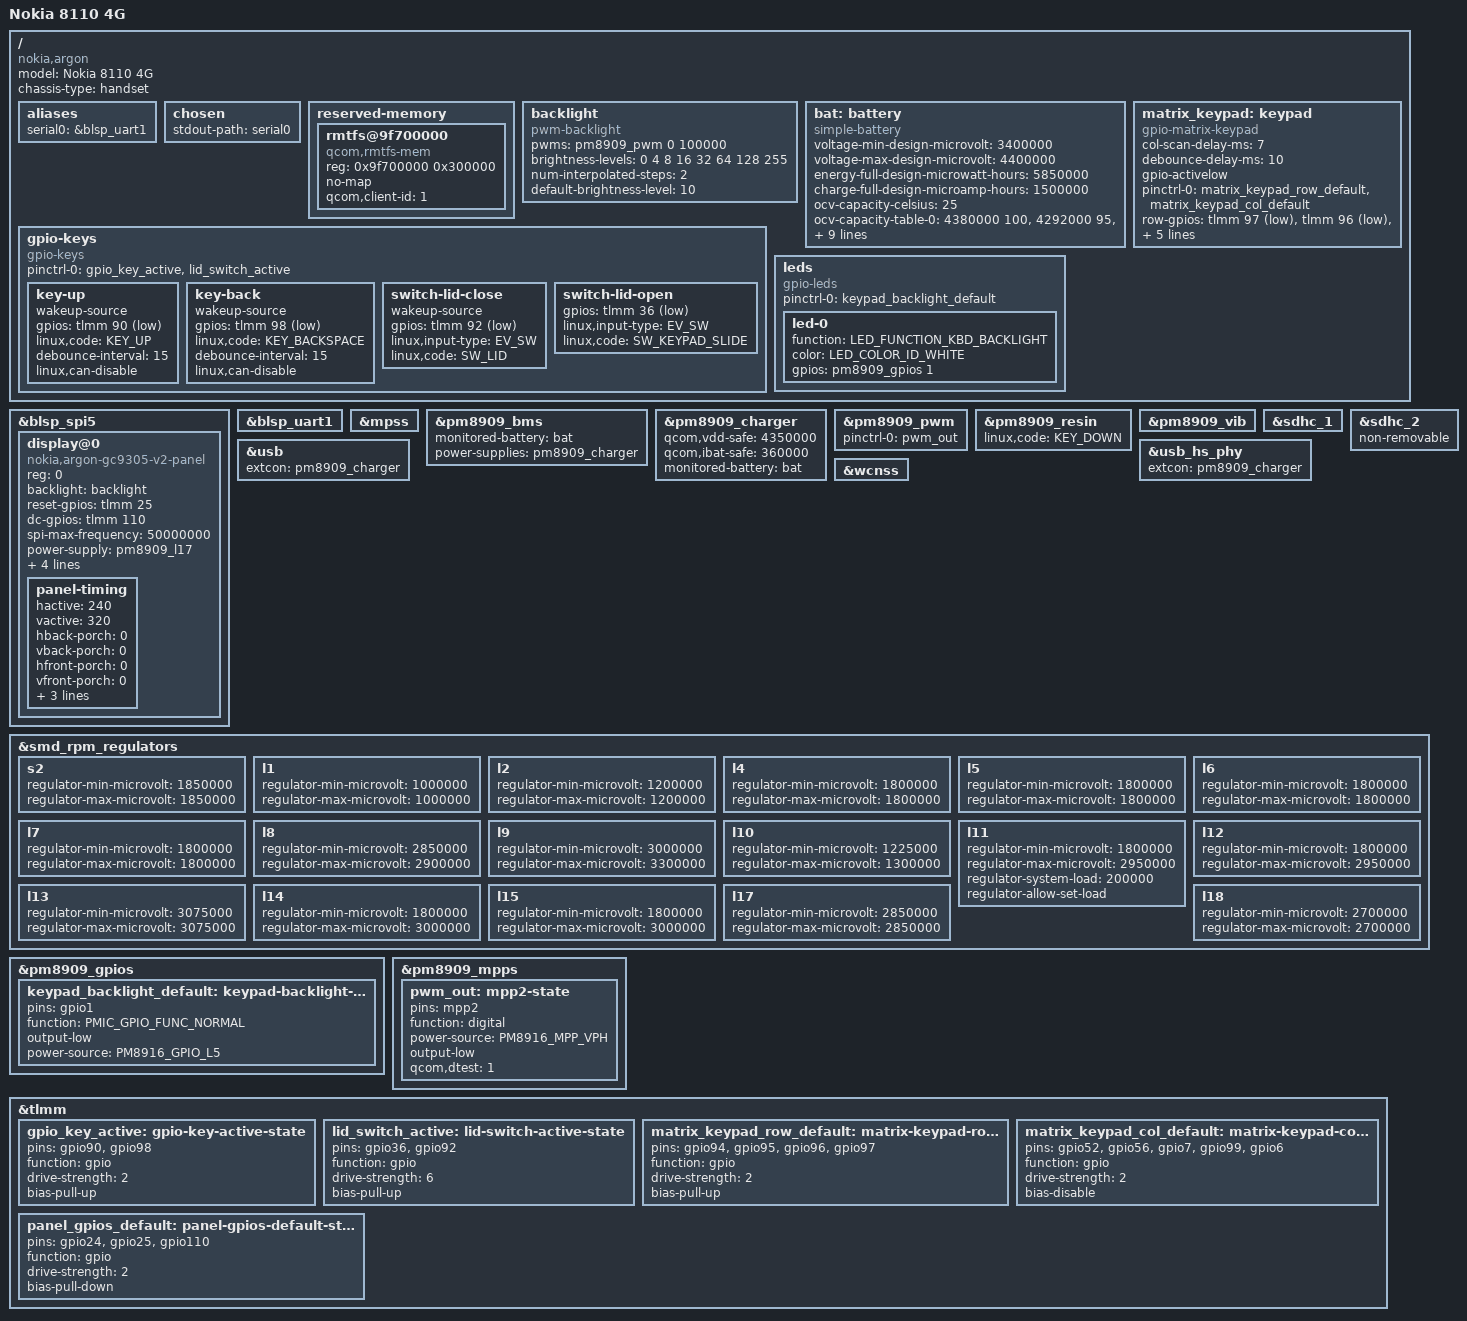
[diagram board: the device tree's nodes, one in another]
// SPDX-License-Identifier: GPL-2.0-only
/dts-v1/;
#include "qcom-msm8909-pm8909.dtsi"
#include <dt-bindings/gpio/gpio.h>
#include <dt-bindings/input/input.h>
#include <dt-bindings/leds/common.h>
#include <dt-bindings/pinctrl/qcom,pmic-gpio.h>
#include <dt-bindings/pinctrl/qcom,pmic-mpp.h>

/ {
	model = "Nokia 8110 4G";
	compatible = "nokia,argon", "qcom,msm8905", "qcom,msm8909";
	chassis-type = "handset";

	aliases {
		serial0 = &blsp_uart1;
	};

	chosen {
		stdout-path = "serial0";
	};

	reserved-memory {
		/delete-node/ rmtfs@87c00000;
		/* On downstream, this address is set by the bootloader */
		rmtfs@9f700000 {
			compatible = "qcom,rmtfs-mem";
			reg = <0x9f700000 0x300000>;
			no-map;

			qcom,client-id = <1>;
		};
	};

	backlight: backlight {
		compatible = "pwm-backlight";
		pwms = <&pm8909_pwm 0 100000>;

		brightness-levels = <0 4 8 16 32 64 128 255>;
		num-interpolated-steps = <2>;
		default-brightness-level = <10>;
	};

	bat: battery {
		compatible = "simple-battery";
		voltage-min-design-microvolt = <3400000>;
		voltage-max-design-microvolt = <4400000>;
		energy-full-design-microwatt-hours = <5850000>;
		charge-full-design-microamp-hours = <1500000>;

		ocv-capacity-celsius = <25>;
		ocv-capacity-table-0 = <4380000 100>, <4292000 95>,
			<4234000 90>, <4190000 85>, <4158000 80>, <4125000 75>,
			<4090000 70>, <4040000 65>, <3988000 60>, <3950000 55>,
			<3925000 50>, <3880000 45>, <3840000 40>, <3800000 35>,
			<3784000 30>, <3761000 25>, <3743000 20>, <3722000 16>,
			<3702000 13>, <3690000 11>, <3688000 10>, <3687000 9>,
			<3685000 8>, <3683000 7>, <3677000 6>, <3656000 5>,
			<3612000 4>, <3554000 3>, <3462000 2>, <3322000 1>,
			<3000000 0>;
	};

	gpio-keys {
		compatible = "gpio-keys";
		pinctrl-0 = <&gpio_key_active &lid_switch_active>;
		pinctrl-names = "default";

		key-up {
			wakeup-source;
			gpios = <&tlmm 90 GPIO_ACTIVE_LOW>;
			linux,code = <KEY_UP>;
			debounce-interval = <15>;
			linux,can-disable;
		};

		key-back {
			wakeup-source;
			gpios = <&tlmm 98 GPIO_ACTIVE_LOW>;
			linux,code = <KEY_BACKSPACE>;
			debounce-interval = <15>;
			linux,can-disable;
		};

		switch-lid-close {
			wakeup-source;
			gpios = <&tlmm 92 GPIO_ACTIVE_LOW>;
			linux,input-type = <EV_SW>;
			linux,code = <SW_LID>;
		};

		switch-lid-open {
			gpios = <&tlmm 36 GPIO_ACTIVE_LOW>;
			linux,input-type = <EV_SW>;
			linux,code = <SW_KEYPAD_SLIDE>;
		};
	};

	matrix_keypad: keypad {
		compatible = "gpio-matrix-keypad";

		col-scan-delay-ms = <7>;
		debounce-delay-ms = <10>;
		gpio-activelow;
		pinctrl-0 = <&matrix_keypad_row_default &matrix_keypad_col_default>;
		pinctrl-names = "default";

		row-gpios = <&tlmm 97 GPIO_ACTIVE_LOW
			&tlmm 96 GPIO_ACTIVE_LOW
			&tlmm 95 GPIO_ACTIVE_LOW
			&tlmm 94 GPIO_ACTIVE_LOW>;

		col-gpios = <&tlmm 52 GPIO_ACTIVE_LOW
			&tlmm 56 GPIO_ACTIVE_LOW
			&tlmm 7 GPIO_ACTIVE_LOW
			&tlmm 99 GPIO_ACTIVE_LOW
			&tlmm 6 GPIO_ACTIVE_LOW>;

		linux,keymap = <
			MATRIX_KEY(0, 0, KEY_PICKUP_PHONE)
			MATRIX_KEY(0, 1, KEY_1)
			MATRIX_KEY(0, 2, KEY_4)
			MATRIX_KEY(0, 3, KEY_7)
			MATRIX_KEY(0, 4, KEY_NUMERIC_STAR)

			MATRIX_KEY(1, 0, KEY_LEFT)
			MATRIX_KEY(1, 1, KEY_2)
			MATRIX_KEY(1, 2, KEY_5)
			MATRIX_KEY(1, 3, KEY_8)
			MATRIX_KEY(1, 4, KEY_0)

			MATRIX_KEY(2, 0, BTN_LEFT)
			MATRIX_KEY(2, 1, KEY_3)
			MATRIX_KEY(2, 2, KEY_6)
			MATRIX_KEY(2, 3, KEY_9)
			MATRIX_KEY(2, 4, KEY_NUMERIC_POUND)

			MATRIX_KEY(3, 0, KEY_ENTER)
			MATRIX_KEY(3, 1, KEY_RIGHT)
			MATRIX_KEY(3, 2, BTN_RIGHT)
		>;
	};

	leds {
		compatible = "gpio-leds";

		pinctrl-0 = <&keypad_backlight_default>;
		pinctrl-names = "default";

		led-0 {
			function = LED_FUNCTION_KBD_BACKLIGHT;
			color = <LED_COLOR_ID_WHITE>;
			gpios = <&pm8909_gpios 1 GPIO_ACTIVE_HIGH>;
		};
	};
};

&blsp_spi5 {
	status = "okay";

	display@0 {
		compatible = "nokia,argon-gc9305-v2-panel", "panel-mipi-dbi-spi";
		reg = <0>;
		backlight = <&backlight>;
		reset-gpios = <&tlmm 25 GPIO_ACTIVE_HIGH>;
		dc-gpios = <&tlmm 110 GPIO_ACTIVE_HIGH>;
		spi-max-frequency = <50000000>;
		power-supply = <&pm8909_l17>;
		io-supply = <&pm8909_l6>;
		width-mm = <36>;
		height-mm = <48>;

		pinctrl-0 = <&panel_gpios_default>;
		pinctrl-names = "default";

		panel-timing {
			hactive = <240>;
			vactive = <320>;
			hback-porch = <0>;
			vback-porch = <0>;
			hfront-porch = <0>;
			vfront-porch = <0>;
			hsync-len = <0>;
			vsync-len = <0>;
			clock-frequency = <(240 * 320 * 30)>; /* 30 fps */
		};
	};
};

&blsp_uart1 {
	status = "okay";
};

&mpss {
	status = "okay";
};

&pm8909_bms {
	monitored-battery = <&bat>;
	power-supplies = <&pm8909_charger>;
	status = "okay";
};

&pm8909_charger {
	qcom,vdd-safe = <4350000>;
	qcom,ibat-safe = <360000>;

	monitored-battery = <&bat>;

	status = "okay";
};

&pm8909_pwm {
	pinctrl-0 = <&pwm_out>;
	pinctrl-names = "default";
	status = "okay";
};

&pm8909_resin {
	linux,code = <KEY_DOWN>;
	status = "okay";
};

&pm8909_vib {
	status = "okay";
};

&sdhc_1 {
	status = "okay";
};

&sdhc_2 {
	non-removable;
	status = "okay";
};

&usb {
	extcon = <&pm8909_charger>;
	status = "okay";
};

&usb_hs_phy {
	extcon = <&pm8909_charger>;
};

&wcnss {
	status = "okay";
};

&smd_rpm_regulators {
	s2 {
		regulator-min-microvolt = <1850000>;
		regulator-max-microvolt = <1850000>;
	};

	l1 {
		regulator-min-microvolt = <1000000>;
		regulator-max-microvolt = <1000000>;
	};

	l2 {
		regulator-min-microvolt = <1200000>;
		regulator-max-microvolt = <1200000>;
	};

	l4 {
		regulator-min-microvolt = <1800000>;
		regulator-max-microvolt = <1800000>;
	};

	l5 {
		regulator-min-microvolt = <1800000>;
		regulator-max-microvolt = <1800000>;
	};

	l6 {
		regulator-min-microvolt = <1800000>;
		regulator-max-microvolt = <1800000>;
	};

	l7 {
		regulator-min-microvolt = <1800000>;
		regulator-max-microvolt = <1800000>;
	};

	l8 {
		regulator-min-microvolt = <2850000>;
		regulator-max-microvolt = <2900000>;
	};

	l9 {
		regulator-min-microvolt = <3000000>;
		regulator-max-microvolt = <3300000>;
	};

	l10 {
		regulator-min-microvolt = <1225000>;
		regulator-max-microvolt = <1300000>;
	};

	l11 {
		regulator-min-microvolt = <1800000>;
		regulator-max-microvolt = <2950000>;
		regulator-system-load = <200000>;
		regulator-allow-set-load;
	};

	l12 {
		regulator-min-microvolt = <1800000>;
		regulator-max-microvolt = <2950000>;
	};

	l13 {
		regulator-min-microvolt = <3075000>;
		regulator-max-microvolt = <3075000>;
	};

	l14 {
		regulator-min-microvolt = <1800000>;
		regulator-max-microvolt = <3000000>;
	};

	l15 {
		regulator-min-microvolt = <1800000>;
		regulator-max-microvolt = <3000000>;
	};

	l17 {
		regulator-min-microvolt = <2850000>;
		regulator-max-microvolt = <2850000>;
	};

	l18 {
		regulator-min-microvolt = <2700000>;
		regulator-max-microvolt = <2700000>;
	};
};

&pm8909_gpios {
	keypad_backlight_default: keypad-backlight-default-state {
		pins = "gpio1";
		function = PMIC_GPIO_FUNC_NORMAL;
		output-low;
		power-source = <PM8916_GPIO_L5>;
	};
};

&pm8909_mpps {
	pwm_out: mpp2-state {
		pins = "mpp2";
		function = "digital";
		power-source = <PM8916_MPP_VPH>;
		output-low;
		qcom,dtest = <1>;
	};
};

&tlmm {
	gpio_key_active: gpio-key-active-state {
		pins = "gpio90", "gpio98";
		function = "gpio";
		drive-strength = <2>;
		bias-pull-up;
	};

	lid_switch_active: lid-switch-active-state {
		pins = "gpio36", "gpio92";
		function = "gpio";
		drive-strength = <6>;
		bias-pull-up;
	};

	matrix_keypad_row_default: matrix-keypad-row-gpio-state {
		pins = "gpio94", "gpio95", "gpio96", "gpio97";
		function = "gpio";
		drive-strength = <2>;
		bias-pull-up;
	};

	matrix_keypad_col_default: matrix-keypad-col-default-state {
		pins = "gpio52", "gpio56", "gpio7", "gpio99", "gpio6";
		function = "gpio";
		drive-strength = <2>;
		bias-disable;
	};

	panel_gpios_default: panel-gpios-default-state {
		pins = "gpio24", "gpio25", "gpio110";
		function = "gpio";
		drive-strength = <2>;
		bias-pull-down;
	};
};
